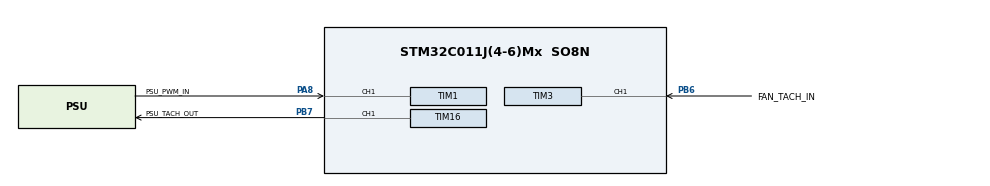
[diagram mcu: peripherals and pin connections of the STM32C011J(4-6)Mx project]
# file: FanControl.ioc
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Dma.Request0=TIM3_CH1
Dma.Request1=TIM1_CH1
Dma.TIM1_CH1.1.Direction=DMA_PERIPH_TO_MEMORY
Dma.TIM1_CH1.1.EventEnable=DISABLE
Dma.TIM1_CH1.1.Instance=DMA1_Channel2
Dma.TIM1_CH1.1.MemDataAlignment=DMA_MDATAALIGN_WORD
Dma.TIM1_CH1.1.MemInc=DMA_MINC_ENABLE
Dma.TIM1_CH1.1.Mode=DMA_CIRCULAR
Dma.TIM1_CH1.1.PeriphDataAlignment=DMA_PDATAALIGN_WORD
Dma.TIM1_CH1.1.PeriphInc=DMA_PINC_ENABLE
Dma.TIM1_CH1.1.Polarity=HAL_DMAMUX_REQ_GEN_RISING
Dma.TIM1_CH1.1.Priority=DMA_PRIORITY_LOW
Dma.TIM1_CH1.1.RequestNumber=1
Dma.TIM1_CH1.1.SignalID=NONE
Dma.TIM1_CH1.1.SyncEnable=DISABLE
Dma.TIM1_CH1.1.SyncPolarity=HAL_DMAMUX_SYNC_NO_EVENT
Dma.TIM1_CH1.1.SyncRequestNumber=1
Dma.TIM1_CH1.1.SyncSignalID=NONE
Dma.TIM3_CH1.0.Direction=DMA_PERIPH_TO_MEMORY
Dma.TIM3_CH1.0.EventEnable=DISABLE
Dma.TIM3_CH1.0.Instance=DMA1_Channel1
Dma.TIM3_CH1.0.MemDataAlignment=DMA_MDATAALIGN_WORD
Dma.TIM3_CH1.0.MemInc=DMA_MINC_ENABLE
Dma.TIM3_CH1.0.Mode=DMA_CIRCULAR
Dma.TIM3_CH1.0.PeriphDataAlignment=DMA_PDATAALIGN_WORD
Dma.TIM3_CH1.0.PeriphInc=DMA_PINC_ENABLE
Dma.TIM3_CH1.0.Polarity=HAL_DMAMUX_REQ_GEN_RISING
Dma.TIM3_CH1.0.Priority=DMA_PRIORITY_LOW
Dma.TIM3_CH1.0.RequestNumber=1
Dma.TIM3_CH1.0.SignalID=NONE
Dma.TIM3_CH1.0.SyncEnable=DISABLE
Dma.TIM3_CH1.0.SyncPolarity=HAL_DMAMUX_SYNC_NO_EVENT
Dma.TIM3_CH1.0.SyncRequestNumber=1
Dma.TIM3_CH1.0.SyncSignalID=NONE
Mcu.Family=STM32C0
Mcu.Name=STM32C011J(4-6)Mx
Mcu.Package=SO8N
NVIC.DMA1_Channel1_IRQn=true\:0\:0\:false\:false\:true\:false\:true\:true
NVIC.DMA1_Channel2_3_IRQn=true\:0\:0\:false\:false\:true\:false\:true\:true
NVIC.TIM1_BRK_UP_TRG_COM_IRQn=true\:0\:0\:false\:false\:true\:true\:true\:true
NVIC.TIM1_CC_IRQn=true\:0\:0\:false\:false\:true\:true\:true\:true
NVIC.TIM3_IRQn=true\:0\:0\:false\:false\:true\:true\:true\:true
PA8.GPIO_Label=PSU_PWM_IN
PA8.Signal=S_TIM1_CH1
PA8__PA11\ [PA9].StandardMode=true
PB6.GPIO_Label=FAN_TACH_IN
PB6.GPIO_ModeDefaultPP=GPIO_MODE_AF_OD
PB6.GPIO_PuPd=GPIO_PULLUP
PB6.Signal=S_TIM3_CH1
PB7.GPIO_Label=PSU_TACH_OUT
PB7.GPIO_ModeDefaultPP=GPIO_MODE_AF_OD
PB7.Signal=S_TIM16_CH1
PC14-OSCX_IN\ (PC14)__PB7.StandardMode=true
PC15-OSCX_OUT\ (PC15)__PA14-BOOT0__PB6.StandardMode=true
PF2-NRST__PA0__PA1__PA2.StandardMode=true
ProjectManager.HeapSize=0x200
ProjectManager.StackSize=0x400
ProjectManager.TargetToolchain=STM32CubeIDE
RCC.ADCFreq_Value=48000000
RCC.AHBFreq_Value=48000000
RCC.CortexFreq_Value=48000000
RCC.EXTERNAL_CLOCK_VALUE=12288000
RCC.HCLKFreq_Value=48000000
RCC.HSE_VALUE=8000000
RCC.HSISYSCLKDivider=RCC_HSI_DIV1
RCC.HSI_VALUE=48000000
RCC.LSE_VALUE=32768
RCC.SYSCLKFreq_VALUE=48000000
SH.S_TIM16_CH1.0=TIM16_CH1,PWM Generation1 CH1
SH.S_TIM1_CH1.0=TIM1_CH1,PWM_Input_1
SH.S_TIM3_CH1.0=TIM3_CH1,PWM_Input_1
TIM1.Prescaler=0
TIM1.TIM_MasterSlaveMode=TIM_MASTERSLAVEMODE_DISABLE
TIM16.Channel=TIM_CHANNEL_1
TIM16.Period=9
TIM16.Prescaler=8000
TIM16.Pulse=5
TIM3.ICPolarity_1=TIM_INPUTCHANNELPOLARITY_FALLING
TIM3.Prescaler=182
VP_TIM16_VS_ClockSourceINT.Mode=Enable_Timer
VP_TIM1_VS_ClockSourceINT.Mode=Internal
VP_TIM3_VS_ClockSourceINT.Mode=Internal
board=custom

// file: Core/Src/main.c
/* USER CODE BEGIN Header */
/**
  ******************************************************************************
  * @file           : main.c
  * @brief          : Main program body
  ******************************************************************************
  * @attention
  *
  * Copyright (c) 2025 STMicroelectronics.
  * All rights reserved.
  *
  * This software is licensed under terms that can be found in the LICENSE file
  * in the root directory of this software component.
  * If no LICENSE file comes with this software, it is provided AS-IS.
  *
  ******************************************************************************
  */
/* USER CODE END Header */
#include "main.h"

/* USER CODE BEGIN Includes */
#include <string.h>
/* USER CODE END Includes */

/* USER CODE BEGIN PTD */

typedef struct
{
	uint32_t ch1;
	uint32_t ch2;
} _reading;

typedef struct
{
	uint32_t freq;
	float duty;
} _measure;

/* USER CODE END PTD */

/* USER CODE BEGIN PM */

#define CONFIG_BASE_ADDR 0x08007800
#define CONFIG_MAGICWORD 0
#define CONFIG_TARGET_RPM_OFFSET 1
#define CONFIG_FAN_RPM_OFFSET 2
#define CONFIG_INITDELAY_OFFSET 3

/* USER CODE END PM */

TIM_HandleTypeDef htim1;
TIM_HandleTypeDef htim3;
TIM_HandleTypeDef htim16;
DMA_HandleTypeDef hdma_tim1_ch1;
DMA_HandleTypeDef hdma_tim3_ch1;

/* USER CODE BEGIN PV */

uint32_t clock = 0;
uint32_t timerFreq = 0;
uint8_t idxReadingFanTach = 0;
uint8_t idxReadingPsuPwm = 0;
_reading readingsFanTach[16];
_measure measurementsFanTach[16];
_reading readingsPsuPwm[16];
_measure measurementsPsuPwm[16];

/* USER CODE END PV */

void SystemClock_Config(void);
static void MX_GPIO_Init(void);
static void MX_DMA_Init(void);
static void MX_TIM1_Init(void);
static void MX_TIM16_Init(void);
static void MX_TIM3_Init(void);

/* USER CODE BEGIN 0 */

inline void AdvanceFanTachDMAMemoryLocation()
{
	if (++idxReadingFanTach >= 16)
	{
		DMA1_Channel1->CMAR = (uint32_t)readingsFanTach;
		idxReadingFanTach = 0;
	}
	else
	{
		DMA1_Channel1->CMAR += sizeof(_reading);
	}
}

inline void AdvancePsuPwmDMAMemoryLocation()
{
	if (++idxReadingPsuPwm >= 16)
	{
		DMA1_Channel2->CMAR = (uint32_t)readingsPsuPwm;
		idxReadingPsuPwm = 0;
	}
	else
	{
		DMA1_Channel2->CMAR += sizeof(_reading);
	}
}

void HAL_TIM_IC_CaptureCallback(TIM_HandleTypeDef *htim)
{
	if (htim->Instance == TIM3)
	{
		if (readingsFanTach[idxReadingFanTach].ch1 != 0)
		{
			measurementsFanTach[idxReadingFanTach].duty = readingsFanTach[idxReadingFanTach].ch2 * 100.0 / readingsFanTach[idxReadingFanTach].ch1;
			measurementsFanTach[idxReadingFanTach].freq = (timerFreq / readingsFanTach[idxReadingFanTach].ch1);
		}
		else
		{
			measurementsFanTach[idxReadingFanTach].duty = 100;
			measurementsFanTach[idxReadingFanTach].freq = 0;
		}

		AdvanceFanTachDMAMemoryLocation();
	}
	else if (htim->Instance == TIM1)
	{
		if (readingsPsuPwm[idxReadingPsuPwm].ch1 != 0)
		{
			measurementsPsuPwm[idxReadingPsuPwm].duty = readingsPsuPwm[idxReadingPsuPwm].ch2 * 100.0 / readingsPsuPwm[idxReadingPsuPwm].ch1;
			measurementsPsuPwm[idxReadingPsuPwm].freq = (clock / readingsPsuPwm[idxReadingPsuPwm].ch1);
		}
		else
		{
			measurementsPsuPwm[idxReadingPsuPwm].duty = 100;
			measurementsPsuPwm[idxReadingPsuPwm].freq = 0;
		}

		AdvancePsuPwmDMAMemoryLocation();
	}
}

void HAL_TIM_PeriodElapsedCallback(TIM_HandleTypeDef *htim)
{
	if (htim->Instance == TIM3)
	{
		measurementsFanTach[idxReadingFanTach].duty = 100;
		measurementsFanTach[idxReadingFanTach].freq = 0;

		AdvanceFanTachDMAMemoryLocation();
	}
	else if (htim->Instance == TIM1)
	{
		measurementsPsuPwm[idxReadingPsuPwm].duty = 100;
		measurementsPsuPwm[idxReadingPsuPwm].freq = 0;

		AdvancePsuPwmDMAMemoryLocation();
	}
}

/* USER CODE END 0 */

int main(void)
{

  /* USER CODE BEGIN 1 */

	uint8_t i = 0;
	uint32_t freqSum = 0;
	uint8_t pwmStatus = 1;
	float dutySum = 0.0;
	float psuPwmDutyCycle = 1.0;
	float adjustmentFactor = 1.0;

	uint32_t *configBase = (uint32_t*)CONFIG_BASE_ADDR;
	uint32_t targetRpm = 18000;
	uint32_t initDelay = 5000;

  /* USER CODE END 1 */

  /* MCU Configuration--------------------------------------------------------*/

  /* Reset of all peripherals, Initializes the Flash interface and the Systick. */
  HAL_Init();

  /* Configure the system clock */
  SystemClock_Config();

  /* USER CODE BEGIN SysInit */

	clock = HAL_RCC_GetHCLKFreq();
	timerFreq = clock / 183; // adjusted for prescaler of TIM1

  /* USER CODE END SysInit */

  /* Initialize all configured peripherals */
  MX_GPIO_Init();
  MX_DMA_Init();
  MX_TIM1_Init();
  MX_TIM16_Init();
  MX_TIM3_Init();
  /* USER CODE BEGIN 2 */

	if (*(configBase + CONFIG_MAGICWORD) == 0xAABBCCDD)
	{
		targetRpm = *(configBase + CONFIG_TARGET_RPM_OFFSET);
		adjustmentFactor = (float)targetRpm / (float)*(configBase + CONFIG_FAN_RPM_OFFSET);
		initDelay = *(configBase + CONFIG_INITDELAY_OFFSET);

		TIM16->PSC = (float)clock / (targetRpm / 60 * 2 * 10) + 1;
	}

  memset(readingsFanTach, 0, 16 * sizeof(_reading));
  memset(measurementsFanTach, 0, 16 * sizeof(_measure));
	memset(readingsPsuPwm, 0, 16 * sizeof(_reading));
	memset(measurementsPsuPwm, 0, 16 * sizeof(_measure));

  HAL_TIM_PWM_Start(&htim16, TIM_CHANNEL_1);

	HAL_TIM_Base_Start_IT(&htim3);
  HAL_TIM_IC_Start_DMA(&htim3, TIM_CHANNEL_1, (uint32_t *)readingsFanTach, 2);
	HAL_TIM_IC_Start(&htim3, TIM_CHANNEL_2);

	HAL_TIM_Base_Start_IT(&htim1);
	HAL_TIM_IC_Start_DMA(&htim1, TIM_CHANNEL_1, (uint32_t *)readingsPsuPwm, 2);
	HAL_TIM_IC_Start(&htim1, TIM_CHANNEL_2);

  /* USER CODE END 2 */

  /* Infinite loop */
  /* USER CODE BEGIN WHILE */

  HAL_Delay(initDelay);

  while (1)
  {
    /* USER CODE END WHILE */

    /* USER CODE BEGIN 3 */

	  freqSum = 0;
	  dutySum = 0;

	  for (i = 0; i < 16; ++i)
    {
	    freqSum += measurementsFanTach[i].freq;
	    dutySum += measurementsPsuPwm[i].duty;
    }

	  psuPwmDutyCycle = dutySum / 1600.0;

	  if (psuPwmDutyCycle < 0.01 || psuPwmDutyCycle > 1)
		  psuPwmDutyCycle = 1.0;

	  if (freqSum < 400) // prevent prescaler register overflow
	  {
		  if (pwmStatus)
		  {
			  HAL_TIM_PWM_Stop(&htim16, TIM_CHANNEL_1);
			  pwmStatus = 0;
		  }
	  }
	  else
	  {
		  TIM16->PSC = (float)clock / (adjustmentFactor*psuPwmDutyCycle*freqSum / 1.6) + 1;

		  if (!pwmStatus)
		  {
			  HAL_TIM_PWM_Start(&htim16, TIM_CHANNEL_1);
			  pwmStatus = 1;
		  }
	  }

	  HAL_Delay(100);
  }
  /* USER CODE END 3 */
}

void SystemClock_Config(void)
{
  RCC_OscInitTypeDef RCC_OscInitStruct = {0};
  RCC_ClkInitTypeDef RCC_ClkInitStruct = {0};

  __HAL_FLASH_SET_LATENCY(FLASH_LATENCY_1);

  /** Initializes the RCC Oscillators according to the specified parameters
  * in the RCC_OscInitTypeDef structure.
  */
  RCC_OscInitStruct.OscillatorType = RCC_OSCILLATORTYPE_HSI;
  RCC_OscInitStruct.HSIState = RCC_HSI_ON;
  RCC_OscInitStruct.HSIDiv = RCC_HSI_DIV1;
  RCC_OscInitStruct.HSICalibrationValue = RCC_HSICALIBRATION_DEFAULT;
  if (HAL_RCC_OscConfig(&RCC_OscInitStruct) != HAL_OK)
  {
    Error_Handler();
  }

  /** Initializes the CPU, AHB and APB buses clocks
  */
  RCC_ClkInitStruct.ClockType = RCC_CLOCKTYPE_HCLK|RCC_CLOCKTYPE_SYSCLK
                              |RCC_CLOCKTYPE_PCLK1;
  RCC_ClkInitStruct.SYSCLKSource = RCC_SYSCLKSOURCE_HSI;
  RCC_ClkInitStruct.SYSCLKDivider = RCC_SYSCLK_DIV1;
  RCC_ClkInitStruct.AHBCLKDivider = RCC_HCLK_DIV1;
  RCC_ClkInitStruct.APB1CLKDivider = RCC_APB1_DIV1;

  if (HAL_RCC_ClockConfig(&RCC_ClkInitStruct, FLASH_LATENCY_1) != HAL_OK)
  {
    Error_Handler();
  }
}

static void MX_TIM1_Init(void)
{

  TIM_ClockConfigTypeDef sClockSourceConfig = {0};
  TIM_SlaveConfigTypeDef sSlaveConfig = {0};
  TIM_IC_InitTypeDef sConfigIC = {0};
  TIM_MasterConfigTypeDef sMasterConfig = {0};

  htim1.Instance = TIM1;
  htim1.Init.Prescaler = 0;
  htim1.Init.CounterMode = TIM_COUNTERMODE_UP;
  htim1.Init.Period = 65535;
  htim1.Init.ClockDivision = TIM_CLOCKDIVISION_DIV1;
  htim1.Init.RepetitionCounter = 0;
  htim1.Init.AutoReloadPreload = TIM_AUTORELOAD_PRELOAD_DISABLE;
  if (HAL_TIM_Base_Init(&htim1) != HAL_OK)
  {
    Error_Handler();
  }
  sClockSourceConfig.ClockSource = TIM_CLOCKSOURCE_INTERNAL;
  if (HAL_TIM_ConfigClockSource(&htim1, &sClockSourceConfig) != HAL_OK)
  {
    Error_Handler();
  }
  if (HAL_TIM_IC_Init(&htim1) != HAL_OK)
  {
    Error_Handler();
  }
  sSlaveConfig.SlaveMode = TIM_SLAVEMODE_RESET;
  sSlaveConfig.InputTrigger = TIM_TS_TI1FP1;
  sSlaveConfig.TriggerPolarity = TIM_INPUTCHANNELPOLARITY_RISING;
  sSlaveConfig.TriggerPrescaler = TIM_ICPSC_DIV1;
  sSlaveConfig.TriggerFilter = 0;
  if (HAL_TIM_SlaveConfigSynchro(&htim1, &sSlaveConfig) != HAL_OK)
  {
    Error_Handler();
  }
  sConfigIC.ICPolarity = TIM_INPUTCHANNELPOLARITY_RISING;
  sConfigIC.ICSelection = TIM_ICSELECTION_DIRECTTI;
  sConfigIC.ICPrescaler = TIM_ICPSC_DIV1;
  sConfigIC.ICFilter = 0;
  if (HAL_TIM_IC_ConfigChannel(&htim1, &sConfigIC, TIM_CHANNEL_1) != HAL_OK)
  {
    Error_Handler();
  }
  sConfigIC.ICPolarity = TIM_INPUTCHANNELPOLARITY_FALLING;
  sConfigIC.ICSelection = TIM_ICSELECTION_INDIRECTTI;
  if (HAL_TIM_IC_ConfigChannel(&htim1, &sConfigIC, TIM_CHANNEL_2) != HAL_OK)
  {
    Error_Handler();
  }
  sMasterConfig.MasterOutputTrigger = TIM_TRGO_RESET;
  sMasterConfig.MasterOutputTrigger2 = TIM_TRGO2_RESET;
  sMasterConfig.MasterSlaveMode = TIM_MASTERSLAVEMODE_DISABLE;
  if (HAL_TIMEx_MasterConfigSynchronization(&htim1, &sMasterConfig) != HAL_OK)
  {
    Error_Handler();
  }
  /* USER CODE BEGIN TIM1_Init 2 */

	__HAL_TIM_CLEAR_FLAG(&htim1, TIM_FLAG_UPDATE);
	__HAL_TIM_URS_ENABLE(&htim1);

  /* USER CODE END TIM1_Init 2 */

}

static void MX_TIM3_Init(void)
{

  TIM_ClockConfigTypeDef sClockSourceConfig = {0};
  TIM_SlaveConfigTypeDef sSlaveConfig = {0};
  TIM_IC_InitTypeDef sConfigIC = {0};
  TIM_MasterConfigTypeDef sMasterConfig = {0};

  htim3.Instance = TIM3;
  htim3.Init.Prescaler = 182;
  htim3.Init.CounterMode = TIM_COUNTERMODE_UP;
  htim3.Init.Period = 65535;
  htim3.Init.ClockDivision = TIM_CLOCKDIVISION_DIV1;
  htim3.Init.AutoReloadPreload = TIM_AUTORELOAD_PRELOAD_DISABLE;
  if (HAL_TIM_Base_Init(&htim3) != HAL_OK)
  {
    Error_Handler();
  }
  sClockSourceConfig.ClockSource = TIM_CLOCKSOURCE_INTERNAL;
  if (HAL_TIM_ConfigClockSource(&htim3, &sClockSourceConfig) != HAL_OK)
  {
    Error_Handler();
  }
  if (HAL_TIM_IC_Init(&htim3) != HAL_OK)
  {
    Error_Handler();
  }
  sSlaveConfig.SlaveMode = TIM_SLAVEMODE_RESET;
  sSlaveConfig.InputTrigger = TIM_TS_TI1FP1;
  sSlaveConfig.TriggerPolarity = TIM_INPUTCHANNELPOLARITY_FALLING;
  sSlaveConfig.TriggerPrescaler = TIM_ICPSC_DIV1;
  sSlaveConfig.TriggerFilter = 0;
  if (HAL_TIM_SlaveConfigSynchro(&htim3, &sSlaveConfig) != HAL_OK)
  {
    Error_Handler();
  }
  sConfigIC.ICPolarity = TIM_INPUTCHANNELPOLARITY_FALLING;
  sConfigIC.ICSelection = TIM_ICSELECTION_DIRECTTI;
  sConfigIC.ICPrescaler = TIM_ICPSC_DIV1;
  sConfigIC.ICFilter = 0;
  if (HAL_TIM_IC_ConfigChannel(&htim3, &sConfigIC, TIM_CHANNEL_1) != HAL_OK)
  {
    Error_Handler();
  }
  sConfigIC.ICPolarity = TIM_INPUTCHANNELPOLARITY_RISING;
  sConfigIC.ICSelection = TIM_ICSELECTION_INDIRECTTI;
  if (HAL_TIM_IC_ConfigChannel(&htim3, &sConfigIC, TIM_CHANNEL_2) != HAL_OK)
  {
    Error_Handler();
  }
  sMasterConfig.MasterOutputTrigger = TIM_TRGO_RESET;
  sMasterConfig.MasterSlaveMode = TIM_MASTERSLAVEMODE_DISABLE;
  if (HAL_TIMEx_MasterConfigSynchronization(&htim3, &sMasterConfig) != HAL_OK)
  {
    Error_Handler();
  }
  /* USER CODE BEGIN TIM3_Init 2 */

	__HAL_TIM_CLEAR_FLAG(&htim3, TIM_FLAG_UPDATE);
	__HAL_TIM_URS_ENABLE(&htim3);

  /* USER CODE END TIM3_Init 2 */

}

static void MX_TIM16_Init(void)
{

  TIM_OC_InitTypeDef sConfigOC = {0};
  TIM_BreakDeadTimeConfigTypeDef sBreakDeadTimeConfig = {0};

  htim16.Instance = TIM16;
  htim16.Init.Prescaler = 8000;
  htim16.Init.CounterMode = TIM_COUNTERMODE_UP;
  htim16.Init.Period = 9;
  htim16.Init.ClockDivision = TIM_CLOCKDIVISION_DIV1;
  htim16.Init.RepetitionCounter = 0;
  htim16.Init.AutoReloadPreload = TIM_AUTORELOAD_PRELOAD_DISABLE;
  if (HAL_TIM_Base_Init(&htim16) != HAL_OK)
  {
    Error_Handler();
  }
  if (HAL_TIM_PWM_Init(&htim16) != HAL_OK)
  {
    Error_Handler();
  }
  sConfigOC.OCMode = TIM_OCMODE_PWM1;
  sConfigOC.Pulse = 5;
  sConfigOC.OCPolarity = TIM_OCPOLARITY_HIGH;
  sConfigOC.OCNPolarity = TIM_OCNPOLARITY_HIGH;
  sConfigOC.OCFastMode = TIM_OCFAST_DISABLE;
  sConfigOC.OCIdleState = TIM_OCIDLESTATE_RESET;
  sConfigOC.OCNIdleState = TIM_OCNIDLESTATE_RESET;
  if (HAL_TIM_PWM_ConfigChannel(&htim16, &sConfigOC, TIM_CHANNEL_1) != HAL_OK)
  {
    Error_Handler();
  }
  sBreakDeadTimeConfig.OffStateRunMode = TIM_OSSR_DISABLE;
  sBreakDeadTimeConfig.OffStateIDLEMode = TIM_OSSI_DISABLE;
  sBreakDeadTimeConfig.LockLevel = TIM_LOCKLEVEL_OFF;
  sBreakDeadTimeConfig.DeadTime = 0;
  sBreakDeadTimeConfig.BreakState = TIM_BREAK_DISABLE;
  sBreakDeadTimeConfig.BreakPolarity = TIM_BREAKPOLARITY_HIGH;
  sBreakDeadTimeConfig.BreakFilter = 0;
  sBreakDeadTimeConfig.AutomaticOutput = TIM_AUTOMATICOUTPUT_DISABLE;
  if (HAL_TIMEx_ConfigBreakDeadTime(&htim16, &sBreakDeadTimeConfig) != HAL_OK)
  {
    Error_Handler();
  }
  HAL_TIM_MspPostInit(&htim16);

}

static void MX_DMA_Init(void)
{

  /* DMA controller clock enable */
  __HAL_RCC_DMA1_CLK_ENABLE();

  /* DMA interrupt init */
  /* DMA1_Channel1_IRQn interrupt configuration */
  HAL_NVIC_SetPriority(DMA1_Channel1_IRQn, 0, 0);
  HAL_NVIC_EnableIRQ(DMA1_Channel1_IRQn);
  /* DMA1_Channel2_3_IRQn interrupt configuration */
  HAL_NVIC_SetPriority(DMA1_Channel2_3_IRQn, 0, 0);
  HAL_NVIC_EnableIRQ(DMA1_Channel2_3_IRQn);

}

static void MX_GPIO_Init(void)
{

  /* GPIO Ports Clock Enable */
  __HAL_RCC_GPIOB_CLK_ENABLE();
  __HAL_RCC_GPIOA_CLK_ENABLE();

}

void Error_Handler(void)
{
  __disable_irq();
  while (1)
  {
  }
}
